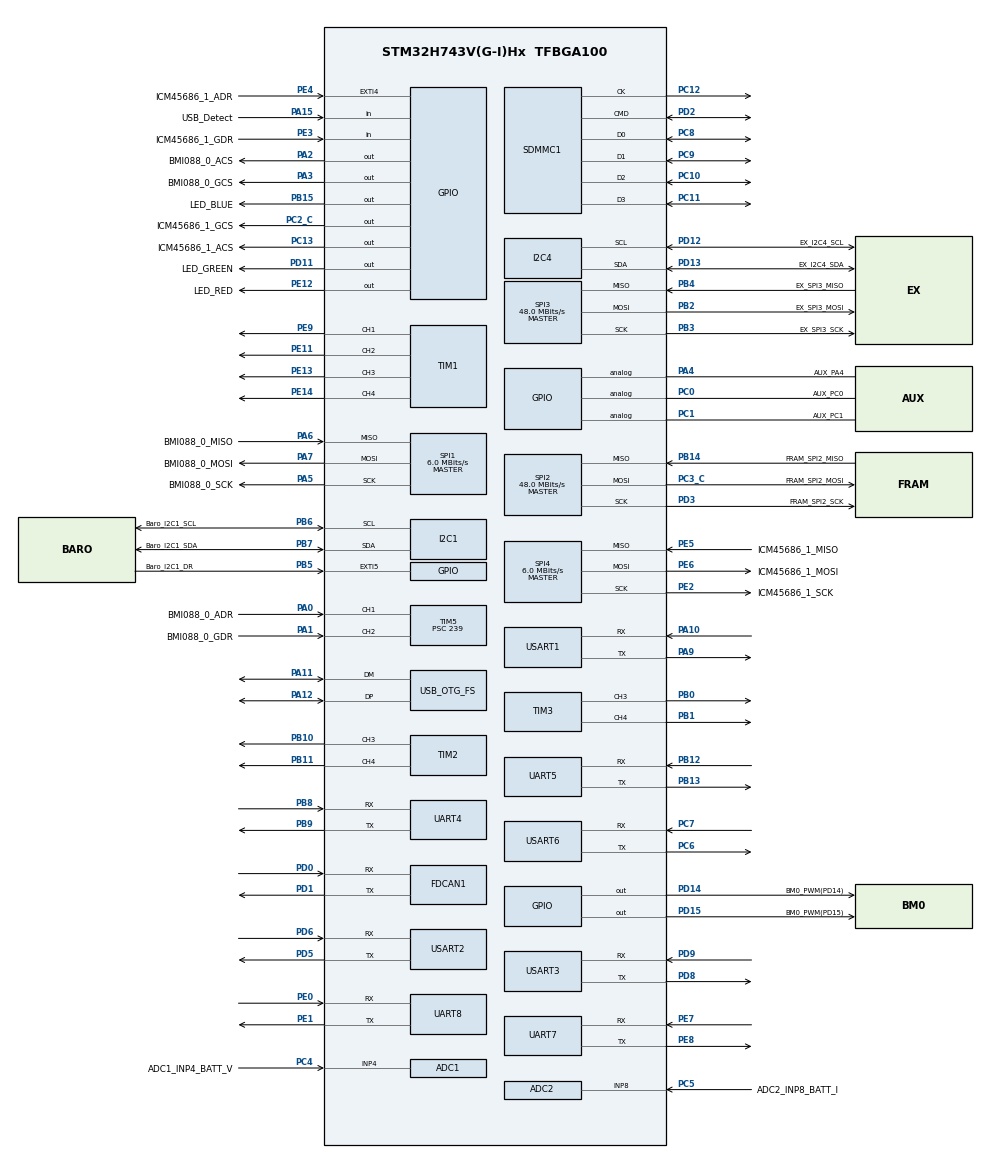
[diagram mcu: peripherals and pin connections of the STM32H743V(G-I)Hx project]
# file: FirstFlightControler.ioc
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ADC1.Channel-1\#ChannelRegularConversion=ADC_CHANNEL_4
ADC1.NbrOfConversionFlag=1
ADC1.OffsetNumber-1\#ChannelRegularConversion=ADC_OFFSET_NONE
ADC1.OffsetSignedSaturation-1\#ChannelRegularConversion=DISABLE
ADC1.Rank-1\#ChannelRegularConversion=1
ADC1.SamplingTime-1\#ChannelRegularConversion=ADC_SAMPLETIME_1CYCLE_5
ADC1.master=1
ADC2.Channel-0\#ChannelRegularConversion=ADC_CHANNEL_8
ADC2.ClockPrescaler=ADC_CLOCK_ASYNC_DIV1
ADC2.NbrOfConversionFlag=1
ADC2.OffsetNumber-0\#ChannelRegularConversion=ADC_OFFSET_NONE
ADC2.OffsetSignedSaturation-0\#ChannelRegularConversion=DISABLE
ADC2.Rank-0\#ChannelRegularConversion=1
ADC2.SamplingTime-0\#ChannelRegularConversion=ADC_SAMPLETIME_1CYCLE_5
CORTEX_M7.CPU_DCache=Disabled
CORTEX_M7.CPU_ICache=Enabled
CORTEX_M7.default_mode_Activation=1
Dma.Request0=USART1_RX
Dma.Request1=USART1_TX
Dma.Request10=SPI1_RX
Dma.Request11=SPI1_TX
Dma.Request12=SPI4_RX
Dma.Request13=SPI4_TX
Dma.Request2=USART2_RX
Dma.Request3=USART2_TX
Dma.Request4=USART3_RX
Dma.Request5=USART3_TX
Dma.Request6=UART5_RX
Dma.Request7=TIM1_UP
Dma.Request8=TIM2_UP
Dma.Request9=TIM3_UP
Dma.SPI1_RX.10.Direction=DMA_PERIPH_TO_MEMORY
Dma.SPI1_RX.10.EventEnable=DISABLE
Dma.SPI1_RX.10.FIFOMode=DMA_FIFOMODE_DISABLE
Dma.SPI1_RX.10.Instance=DMA1_Stream3
Dma.SPI1_RX.10.MemDataAlignment=DMA_MDATAALIGN_BYTE
Dma.SPI1_RX.10.MemInc=DMA_MINC_ENABLE
Dma.SPI1_RX.10.Mode=DMA_NORMAL
Dma.SPI1_RX.10.PeriphDataAlignment=DMA_PDATAALIGN_BYTE
Dma.SPI1_RX.10.PeriphInc=DMA_PINC_DISABLE
Dma.SPI1_RX.10.Polarity=HAL_DMAMUX_REQ_GEN_RISING
Dma.SPI1_RX.10.Priority=DMA_PRIORITY_VERY_HIGH
Dma.SPI1_RX.10.RequestNumber=1
Dma.SPI1_RX.10.SignalID=NONE
Dma.SPI1_RX.10.SyncEnable=DISABLE
Dma.SPI1_RX.10.SyncPolarity=HAL_DMAMUX_SYNC_NO_EVENT
Dma.SPI1_RX.10.SyncRequestNumber=1
Dma.SPI1_RX.10.SyncSignalID=NONE
Dma.SPI1_TX.11.Direction=DMA_MEMORY_TO_PERIPH
Dma.SPI1_TX.11.EventEnable=DISABLE
Dma.SPI1_TX.11.FIFOMode=DMA_FIFOMODE_DISABLE
Dma.SPI1_TX.11.Instance=DMA1_Stream4
Dma.SPI1_TX.11.MemDataAlignment=DMA_MDATAALIGN_BYTE
Dma.SPI1_TX.11.MemInc=DMA_MINC_ENABLE
Dma.SPI1_TX.11.Mode=DMA_NORMAL
Dma.SPI1_TX.11.PeriphDataAlignment=DMA_PDATAALIGN_BYTE
Dma.SPI1_TX.11.PeriphInc=DMA_PINC_DISABLE
Dma.SPI1_TX.11.Polarity=HAL_DMAMUX_REQ_GEN_RISING
Dma.SPI1_TX.11.Priority=DMA_PRIORITY_HIGH
Dma.SPI1_TX.11.RequestNumber=1
Dma.SPI1_TX.11.SignalID=NONE
Dma.SPI1_TX.11.SyncEnable=DISABLE
Dma.SPI1_TX.11.SyncPolarity=HAL_DMAMUX_SYNC_NO_EVENT
Dma.SPI1_TX.11.SyncRequestNumber=1
Dma.SPI1_TX.11.SyncSignalID=NONE
Dma.SPI4_RX.12.Direction=DMA_PERIPH_TO_MEMORY
Dma.SPI4_RX.12.EventEnable=DISABLE
Dma.SPI4_RX.12.FIFOMode=DMA_FIFOMODE_DISABLE
Dma.SPI4_RX.12.Instance=DMA1_Stream5
Dma.SPI4_RX.12.MemDataAlignment=DMA_MDATAALIGN_BYTE
Dma.SPI4_RX.12.MemInc=DMA_MINC_ENABLE
Dma.SPI4_RX.12.Mode=DMA_NORMAL
Dma.SPI4_RX.12.PeriphDataAlignment=DMA_PDATAALIGN_BYTE
Dma.SPI4_RX.12.PeriphInc=DMA_PINC_DISABLE
Dma.SPI4_RX.12.Polarity=HAL_DMAMUX_REQ_GEN_RISING
Dma.SPI4_RX.12.Priority=DMA_PRIORITY_VERY_HIGH
Dma.SPI4_RX.12.RequestNumber=1
Dma.SPI4_RX.12.SignalID=NONE
Dma.SPI4_RX.12.SyncEnable=DISABLE
Dma.SPI4_RX.12.SyncPolarity=HAL_DMAMUX_SYNC_NO_EVENT
Dma.SPI4_RX.12.SyncRequestNumber=1
Dma.SPI4_RX.12.SyncSignalID=NONE
Dma.SPI4_TX.13.Direction=DMA_MEMORY_TO_PERIPH
Dma.SPI4_TX.13.EventEnable=DISABLE
Dma.SPI4_TX.13.FIFOMode=DMA_FIFOMODE_DISABLE
Dma.SPI4_TX.13.Instance=DMA1_Stream6
Dma.SPI4_TX.13.MemDataAlignment=DMA_MDATAALIGN_BYTE
Dma.SPI4_TX.13.MemInc=DMA_MINC_ENABLE
Dma.SPI4_TX.13.Mode=DMA_NORMAL
Dma.SPI4_TX.13.PeriphDataAlignment=DMA_PDATAALIGN_BYTE
Dma.SPI4_TX.13.PeriphInc=DMA_PINC_DISABLE
Dma.SPI4_TX.13.Polarity=HAL_DMAMUX_REQ_GEN_RISING
Dma.SPI4_TX.13.Priority=DMA_PRIORITY_HIGH
Dma.SPI4_TX.13.RequestNumber=1
Dma.SPI4_TX.13.SignalID=NONE
Dma.SPI4_TX.13.SyncEnable=DISABLE
Dma.SPI4_TX.13.SyncPolarity=HAL_DMAMUX_SYNC_NO_EVENT
Dma.SPI4_TX.13.SyncRequestNumber=1
Dma.SPI4_TX.13.SyncSignalID=NONE
Dma.TIM1_UP.7.Direction=DMA_PERIPH_TO_MEMORY
Dma.TIM1_UP.7.EventEnable=DISABLE
Dma.TIM1_UP.7.FIFOMode=DMA_FIFOMODE_DISABLE
Dma.TIM1_UP.7.Instance=DMA1_Stream0
Dma.TIM1_UP.7.MemDataAlignment=DMA_MDATAALIGN_HALFWORD
Dma.TIM1_UP.7.MemInc=DMA_MINC_ENABLE
Dma.TIM1_UP.7.Mode=DMA_NORMAL
Dma.TIM1_UP.7.PeriphDataAlignment=DMA_PDATAALIGN_HALFWORD
Dma.TIM1_UP.7.PeriphInc=DMA_PINC_DISABLE
Dma.TIM1_UP.7.Polarity=HAL_DMAMUX_REQ_GEN_RISING
Dma.TIM1_UP.7.Priority=DMA_PRIORITY_LOW
Dma.TIM1_UP.7.RequestNumber=1
Dma.TIM1_UP.7.SignalID=NONE
Dma.TIM1_UP.7.SyncEnable=DISABLE
Dma.TIM1_UP.7.SyncPolarity=HAL_DMAMUX_SYNC_NO_EVENT
Dma.TIM1_UP.7.SyncRequestNumber=1
Dma.TIM1_UP.7.SyncSignalID=NONE
Dma.TIM2_UP.8.Direction=DMA_PERIPH_TO_MEMORY
Dma.TIM2_UP.8.EventEnable=DISABLE
Dma.TIM2_UP.8.FIFOMode=DMA_FIFOMODE_DISABLE
Dma.TIM2_UP.8.Instance=DMA1_Stream1
Dma.TIM2_UP.8.MemDataAlignment=DMA_MDATAALIGN_WORD
Dma.TIM2_UP.8.MemInc=DMA_MINC_ENABLE
Dma.TIM2_UP.8.Mode=DMA_NORMAL
Dma.TIM2_UP.8.PeriphDataAlignment=DMA_PDATAALIGN_WORD
Dma.TIM2_UP.8.PeriphInc=DMA_PINC_DISABLE
Dma.TIM2_UP.8.Polarity=HAL_DMAMUX_REQ_GEN_RISING
Dma.TIM2_UP.8.Priority=DMA_PRIORITY_LOW
Dma.TIM2_UP.8.RequestNumber=1
Dma.TIM2_UP.8.SignalID=NONE
Dma.TIM2_UP.8.SyncEnable=DISABLE
Dma.TIM2_UP.8.SyncPolarity=HAL_DMAMUX_SYNC_NO_EVENT
Dma.TIM2_UP.8.SyncRequestNumber=1
Dma.TIM2_UP.8.SyncSignalID=NONE
Dma.TIM3_UP.9.Direction=DMA_PERIPH_TO_MEMORY
Dma.TIM3_UP.9.EventEnable=DISABLE
Dma.TIM3_UP.9.FIFOMode=DMA_FIFOMODE_DISABLE
Dma.TIM3_UP.9.Instance=DMA1_Stream2
Dma.TIM3_UP.9.MemDataAlignment=DMA_MDATAALIGN_HALFWORD
Dma.TIM3_UP.9.MemInc=DMA_MINC_ENABLE
Dma.TIM3_UP.9.Mode=DMA_NORMAL
Dma.TIM3_UP.9.PeriphDataAlignment=DMA_PDATAALIGN_HALFWORD
Dma.TIM3_UP.9.PeriphInc=DMA_PINC_DISABLE
Dma.TIM3_UP.9.Polarity=HAL_DMAMUX_REQ_GEN_RISING
Dma.TIM3_UP.9.Priority=DMA_PRIORITY_LOW
Dma.TIM3_UP.9.RequestNumber=1
Dma.TIM3_UP.9.SignalID=NONE
Dma.TIM3_UP.9.SyncEnable=DISABLE
Dma.TIM3_UP.9.SyncPolarity=HAL_DMAMUX_SYNC_NO_EVENT
Dma.TIM3_UP.9.SyncRequestNumber=1
Dma.TIM3_UP.9.SyncSignalID=NONE
Dma.UART5_RX.6.Direction=DMA_PERIPH_TO_MEMORY
Dma.UART5_RX.6.EventEnable=DISABLE
Dma.UART5_RX.6.FIFOMode=DMA_FIFOMODE_DISABLE
Dma.UART5_RX.6.Instance=DMA2_Stream6
Dma.UART5_RX.6.MemDataAlignment=DMA_MDATAALIGN_BYTE
Dma.UART5_RX.6.MemInc=DMA_MINC_ENABLE
Dma.UART5_RX.6.Mode=DMA_NORMAL
Dma.UART5_RX.6.PeriphDataAlignment=DMA_PDATAALIGN_BYTE
Dma.UART5_RX.6.PeriphInc=DMA_PINC_DISABLE
Dma.UART5_RX.6.Polarity=HAL_DMAMUX_REQ_GEN_RISING
Dma.UART5_RX.6.Priority=DMA_PRIORITY_LOW
Dma.UART5_RX.6.RequestNumber=1
Dma.UART5_RX.6.SignalID=NONE
Dma.UART5_RX.6.SyncEnable=DISABLE
Dma.UART5_RX.6.SyncPolarity=HAL_DMAMUX_SYNC_NO_EVENT
Dma.UART5_RX.6.SyncRequestNumber=1
Dma.UART5_RX.6.SyncSignalID=NONE
Dma.USART1_RX.0.Direction=DMA_PERIPH_TO_MEMORY
Dma.USART1_RX.0.EventEnable=DISABLE
Dma.USART1_RX.0.FIFOMode=DMA_FIFOMODE_DISABLE
Dma.USART1_RX.0.Instance=DMA2_Stream0
Dma.USART1_RX.0.MemDataAlignment=DMA_MDATAALIGN_BYTE
Dma.USART1_RX.0.MemInc=DMA_MINC_ENABLE
Dma.USART1_RX.0.Mode=DMA_NORMAL
Dma.USART1_RX.0.PeriphDataAlignment=DMA_PDATAALIGN_BYTE
Dma.USART1_RX.0.PeriphInc=DMA_PINC_DISABLE
Dma.USART1_RX.0.Polarity=HAL_DMAMUX_REQ_GEN_RISING
Dma.USART1_RX.0.Priority=DMA_PRIORITY_LOW
Dma.USART1_RX.0.RequestNumber=1
Dma.USART1_RX.0.SignalID=NONE
Dma.USART1_RX.0.SyncEnable=DISABLE
Dma.USART1_RX.0.SyncPolarity=HAL_DMAMUX_SYNC_NO_EVENT
Dma.USART1_RX.0.SyncRequestNumber=1
Dma.USART1_RX.0.SyncSignalID=NONE
Dma.USART1_TX.1.Direction=DMA_MEMORY_TO_PERIPH
Dma.USART1_TX.1.EventEnable=DISABLE
Dma.USART1_TX.1.FIFOMode=DMA_FIFOMODE_DISABLE
Dma.USART1_TX.1.Instance=DMA2_Stream1
Dma.USART1_TX.1.MemDataAlignment=DMA_MDATAALIGN_BYTE
Dma.USART1_TX.1.MemInc=DMA_MINC_ENABLE
Dma.USART1_TX.1.Mode=DMA_NORMAL
Dma.USART1_TX.1.PeriphDataAlignment=DMA_PDATAALIGN_BYTE
Dma.USART1_TX.1.PeriphInc=DMA_PINC_DISABLE
Dma.USART1_TX.1.Polarity=HAL_DMAMUX_REQ_GEN_RISING
Dma.USART1_TX.1.Priority=DMA_PRIORITY_LOW
Dma.USART1_TX.1.RequestNumber=1
Dma.USART1_TX.1.SignalID=NONE
Dma.USART1_TX.1.SyncEnable=DISABLE
Dma.USART1_TX.1.SyncPolarity=HAL_DMAMUX_SYNC_NO_EVENT
Dma.USART1_TX.1.SyncRequestNumber=1
Dma.USART1_TX.1.SyncSignalID=NONE
Dma.USART2_RX.2.Direction=DMA_PERIPH_TO_MEMORY
Dma.USART2_RX.2.EventEnable=DISABLE
Dma.USART2_RX.2.FIFOMode=DMA_FIFOMODE_DISABLE
Dma.USART2_RX.2.Instance=DMA2_Stream2
Dma.USART2_RX.2.MemDataAlignment=DMA_MDATAALIGN_BYTE
Dma.USART2_RX.2.MemInc=DMA_MINC_ENABLE
Dma.USART2_RX.2.Mode=DMA_NORMAL
Dma.USART2_RX.2.PeriphDataAlignment=DMA_PDATAALIGN_BYTE
Dma.USART2_RX.2.PeriphInc=DMA_PINC_DISABLE
Dma.USART2_RX.2.Polarity=HAL_DMAMUX_REQ_GEN_RISING
Dma.USART2_RX.2.Priority=DMA_PRIORITY_LOW
Dma.USART2_RX.2.RequestNumber=1
Dma.USART2_RX.2.SignalID=NONE
Dma.USART2_RX.2.SyncEnable=DISABLE
Dma.USART2_RX.2.SyncPolarity=HAL_DMAMUX_SYNC_NO_EVENT
Dma.USART2_RX.2.SyncRequestNumber=1
Dma.USART2_RX.2.SyncSignalID=NONE
Dma.USART2_TX.3.Direction=DMA_MEMORY_TO_PERIPH
Dma.USART2_TX.3.EventEnable=DISABLE
Dma.USART2_TX.3.FIFOMode=DMA_FIFOMODE_DISABLE
Dma.USART2_TX.3.Instance=DMA2_Stream3
Dma.USART2_TX.3.MemDataAlignment=DMA_MDATAALIGN_BYTE
Dma.USART2_TX.3.MemInc=DMA_MINC_ENABLE
Dma.USART2_TX.3.Mode=DMA_NORMAL
Dma.USART2_TX.3.PeriphDataAlignment=DMA_PDATAALIGN_BYTE
Dma.USART2_TX.3.PeriphInc=DMA_PINC_DISABLE
Dma.USART2_TX.3.Polarity=HAL_DMAMUX_REQ_GEN_RISING
Dma.USART2_TX.3.Priority=DMA_PRIORITY_LOW
Dma.USART2_TX.3.RequestNumber=1
Dma.USART2_TX.3.SignalID=NONE
Dma.USART2_TX.3.SyncEnable=DISABLE
Dma.USART2_TX.3.SyncPolarity=HAL_DMAMUX_SYNC_NO_EVENT
Dma.USART2_TX.3.SyncRequestNumber=1
Dma.USART2_TX.3.SyncSignalID=NONE
Dma.USART3_RX.4.Direction=DMA_PERIPH_TO_MEMORY
Dma.USART3_RX.4.EventEnable=DISABLE
Dma.USART3_RX.4.FIFOMode=DMA_FIFOMODE_DISABLE
Dma.USART3_RX.4.Instance=DMA2_Stream4
Dma.USART3_RX.4.MemDataAlignment=DMA_MDATAALIGN_BYTE
Dma.USART3_RX.4.MemInc=DMA_MINC_ENABLE
Dma.USART3_RX.4.Mode=DMA_NORMAL
Dma.USART3_RX.4.PeriphDataAlignment=DMA_PDATAALIGN_BYTE
Dma.USART3_RX.4.PeriphInc=DMA_PINC_DISABLE
Dma.USART3_RX.4.Polarity=HAL_DMAMUX_REQ_GEN_RISING
Dma.USART3_RX.4.Priority=DMA_PRIORITY_LOW
Dma.USART3_RX.4.RequestNumber=1
Dma.USART3_RX.4.SignalID=NONE
Dma.USART3_RX.4.SyncEnable=DISABLE
Dma.USART3_RX.4.SyncPolarity=HAL_DMAMUX_SYNC_NO_EVENT
Dma.USART3_RX.4.SyncRequestNumber=1
Dma.USART3_RX.4.SyncSignalID=NONE
Dma.USART3_TX.5.Direction=DMA_MEMORY_TO_PERIPH
Dma.USART3_TX.5.EventEnable=DISABLE
Dma.USART3_TX.5.FIFOMode=DMA_FIFOMODE_DISABLE
Dma.USART3_TX.5.Instance=DMA2_Stream5
Dma.USART3_TX.5.MemDataAlignment=DMA_MDATAALIGN_BYTE
Dma.USART3_TX.5.MemInc=DMA_MINC_ENABLE
Dma.USART3_TX.5.Mode=DMA_NORMAL
Dma.USART3_TX.5.PeriphDataAlignment=DMA_PDATAALIGN_BYTE
Dma.USART3_TX.5.PeriphInc=DMA_PINC_DISABLE
Dma.USART3_TX.5.Polarity=HAL_DMAMUX_REQ_GEN_RISING
Dma.USART3_TX.5.Priority=DMA_PRIORITY_LOW
Dma.USART3_TX.5.RequestNumber=1
Dma.USART3_TX.5.SignalID=NONE
Dma.USART3_TX.5.SyncEnable=DISABLE
Dma.USART3_TX.5.SyncPolarity=HAL_DMAMUX_SYNC_NO_EVENT
Dma.USART3_TX.5.SyncRequestNumber=1
Dma.USART3_TX.5.SyncSignalID=NONE
FDCAN1.CalculateBaudRateNominal=333333
FDCAN1.CalculateTimeBitNominal=3000
FDCAN1.CalculateTimeQuantumNominal=1000.0
I2C1.Timing=0x10707DBC
I2C4.Timing=0x10707DBC
Mcu.Family=STM32H7
Mcu.Name=STM32H743V(G-I)Hx
Mcu.Package=TFBGA100
NVIC.DMA1_Stream0_IRQn=true\:0\:0\:false\:false\:true\:false\:true\:true
NVIC.DMA1_Stream1_IRQn=true\:0\:0\:false\:false\:true\:false\:true\:true
NVIC.DMA1_Stream2_IRQn=true\:0\:0\:false\:false\:true\:false\:true\:true
NVIC.DMA1_Stream3_IRQn=true\:3\:0\:false\:false\:true\:false\:true\:true
NVIC.DMA1_Stream4_IRQn=true\:4\:0\:false\:false\:true\:false\:true\:true
NVIC.DMA1_Stream5_IRQn=true\:3\:0\:false\:false\:true\:false\:true\:true
NVIC.DMA1_Stream6_IRQn=true\:4\:0\:false\:false\:true\:false\:true\:true
NVIC.DMA2_Stream0_IRQn=true\:0\:0\:false\:false\:true\:false\:true\:true
NVIC.DMA2_Stream1_IRQn=true\:0\:0\:false\:false\:true\:false\:true\:true
NVIC.DMA2_Stream2_IRQn=true\:0\:0\:false\:false\:true\:false\:true\:true
NVIC.DMA2_Stream3_IRQn=true\:0\:0\:false\:false\:true\:false\:true\:true
NVIC.DMA2_Stream4_IRQn=true\:0\:0\:false\:false\:true\:false\:true\:true
NVIC.DMA2_Stream5_IRQn=true\:0\:0\:false\:false\:true\:false\:true\:true
NVIC.DMA2_Stream6_IRQn=true\:0\:0\:false\:false\:true\:false\:true\:true
NVIC.EXTI4_IRQn=true\:2\:0\:true\:false\:true\:true\:true\:true
NVIC.OTG_FS_IRQn=true\:0\:0\:false\:false\:true\:false\:true\:true
NVIC.PriorityGroup=NVIC_PRIORITYGROUP_4
NVIC.SPI1_IRQn=true\:4\:0\:false\:false\:true\:false\:true\:true
NVIC.SPI4_IRQn=true\:4\:0\:false\:false\:true\:false\:true\:true
NVIC.TIM5_IRQn=true\:1\:0\:false\:false\:true\:true\:true\:true
PA0.GPIO_Label=BMI088_0_ADR
PA0.Signal=S_TIM5_CH1
PA1.GPIO_Label=BMI088_0_GDR
PA1.Signal=S_TIM5_CH2
PA10.Mode=Asynchronous
PA10.Signal=USART1_RX
PA11.Mode=Device_Only
PA11.Signal=USB_OTG_FS_DM
PA12.Mode=Device_Only
PA12.Signal=USB_OTG_FS_DP
PA13\ (JTMS/SWDIO).Mode=Serial_Wire
PA13\ (JTMS/SWDIO).Signal=DEBUG_JTMS-SWDIO
PA14\ (JTCK/SWCLK).Mode=Serial_Wire
PA14\ (JTCK/SWCLK).Signal=DEBUG_JTCK-SWCLK
PA15\ (JTDI).GPIO_Label=USB_Detect
PA15\ (JTDI).Signal=GPIO_Input
PA2.GPIO_Label=BMI088_0_ACS
PA2.PinState=GPIO_PIN_SET
PA2.Signal=GPIO_Output
PA3.GPIO_Label=BMI088_0_GCS
PA3.PinState=GPIO_PIN_SET
PA3.Signal=GPIO_Output
PA4.GPIO_Label=AUX_PA4
PA4.Signal=GPIO_Analog
PA5.GPIO_Label=BMI088_0_SCK
PA5.Mode=Full_Duplex_Master
PA5.Signal=SPI1_SCK
PA6.GPIO_Label=BMI088_0_MISO
PA6.Mode=Full_Duplex_Master
PA6.Signal=SPI1_MISO
PA7.GPIO_Label=BMI088_0_MOSI
PA7.Mode=Full_Duplex_Master
PA7.Signal=SPI1_MOSI
PA8.Signal=USART1_CK
PA9.Mode=Asynchronous
PA9.Signal=USART1_TX
PB0.Signal=S_TIM3_CH3
PB1.Signal=S_TIM3_CH4
PB10.Signal=S_TIM2_CH3
PB11.Signal=S_TIM2_CH4
PB12.Mode=Asynchronous
PB12.Signal=UART5_RX
PB13.Mode=Asynchronous
PB13.Signal=UART5_TX
PB14.GPIO_Label=FRAM_SPI2_MISO
PB14.Mode=Full_Duplex_Master
PB14.Signal=SPI2_MISO
PB15.GPIO_Label=LED_BLUE
PB15.Signal=GPIO_Output
PB2.GPIO_Label=EX_SPI3_MOSI
PB2.Mode=Full_Duplex_Master
PB2.Signal=SPI3_MOSI
PB3\ (JTDO/TRACESWO).GPIO_Label=EX_SPI3_SCK
PB3\ (JTDO/TRACESWO).Mode=Full_Duplex_Master
PB3\ (JTDO/TRACESWO).Signal=SPI3_SCK
PB4\ (NJTRST).GPIO_Label=EX_SPI3_MISO
PB4\ (NJTRST).Mode=Full_Duplex_Master
PB4\ (NJTRST).Signal=SPI3_MISO
PB5.GPIO_Label=Baro_I2C1_DR
PB5.Signal=GPXTI5
PB6.GPIO_Label=Baro_I2C1_SCL
PB6.Mode=I2C
PB6.Signal=I2C1_SCL
PB7.GPIO_Label=Baro_I2C1_SDA
PB7.Mode=I2C
PB7.Signal=I2C1_SDA
PB8.Mode=Asynchronous
PB8.Signal=UART4_RX
PB9.Mode=Asynchronous
PB9.Signal=UART4_TX
PC0.GPIO_Label=AUX_PC0
PC0.Signal=GPIO_Analog
PC1.GPIO_Label=AUX_PC1
PC1.Signal=GPIO_Analog
PC10.Mode=SD_4_bits_Wide_bus
PC10.Signal=SDMMC1_D2
PC11.Mode=SD_4_bits_Wide_bus
PC11.Signal=SDMMC1_D3
PC12.Mode=SD_4_bits_Wide_bus
PC12.Signal=SDMMC1_CK
PC13.GPIO_Label=ICM45686_1_ACS
PC13.PinState=GPIO_PIN_SET
PC13.Signal=GPIO_Output
PC14-OSC32_IN\ (OSC32_IN).Mode=LSE-External-Oscillator
PC14-OSC32_IN\ (OSC32_IN).Signal=RCC_OSC32_IN
PC15-OSC32_OUT\ (OSC32_OUT).Mode=LSE-External-Oscillator
PC15-OSC32_OUT\ (OSC32_OUT).Signal=RCC_OSC32_OUT
PC2_C.GPIO_Label=ICM45686_1_GCS
PC2_C.PinState=GPIO_PIN_SET
PC2_C.Signal=GPIO_Output
PC3_C.GPIO_Label=FRAM_SPI2_MOSI
PC3_C.Mode=Full_Duplex_Master
PC3_C.Signal=SPI2_MOSI
PC4.GPIO_Label=ADC1_INP4_BATT_V
PC4.Signal=ADCx_INP4
PC5.GPIO_Label=ADC2_INP8_BATT_I
PC5.Signal=SharedAnalog_PC5
PC6.Mode=Asynchronous
PC6.Signal=USART6_TX
PC7.Mode=Asynchronous
PC7.Signal=USART6_RX
PC8.Mode=SD_4_bits_Wide_bus
PC8.Signal=SDMMC1_D0
PC9.Mode=SD_4_bits_Wide_bus
PC9.Signal=SDMMC1_D1
PD0.Mode=FDCAN_Activate
PD0.Signal=FDCAN1_RX
PD1.Mode=FDCAN_Activate
PD1.Signal=FDCAN1_TX
PD10.Signal=USART3_CK
PD11.GPIO_Label=LED_GREEN
PD11.Signal=GPIO_Output
PD12.GPIO_Label=EX_I2C4_SCL
PD12.Mode=I2C
PD12.Signal=I2C4_SCL
PD13.GPIO_Label=EX_I2C4_SDA
PD13.Mode=I2C
PD13.Signal=I2C4_SDA
PD14.GPIO_Label=BM0_PWM(PD14)
PD14.Signal=GPIO_Output
PD15.GPIO_Label=BM0_PWM(PD15)
PD15.Signal=GPIO_Output
PD2.Mode=SD_4_bits_Wide_bus
PD2.Signal=SDMMC1_CMD
PD3.GPIO_Label=FRAM_SPI2_SCK
PD3.Mode=Full_Duplex_Master
PD3.Signal=SPI2_SCK
PD5.Mode=Asynchronous
PD5.Signal=USART2_TX
PD6.Mode=Asynchronous
PD6.Signal=USART2_RX
PD7.Signal=USART2_CK
PD8.Mode=Asynchronous
PD8.Signal=USART3_TX
PD9.Mode=Asynchronous
PD9.Signal=USART3_RX
PE0.Mode=Asynchronous
PE0.Signal=UART8_RX
PE1.Mode=Asynchronous
PE1.Signal=UART8_TX
PE11.Signal=S_TIM1_CH2
PE12.GPIO_Label=LED_RED
PE12.Signal=GPIO_Output
PE13.Signal=S_TIM1_CH3
PE14.Signal=S_TIM1_CH4
PE2.GPIO_Label=ICM45686_1_SCK
PE2.Mode=Full_Duplex_Master
PE2.Signal=SPI4_SCK
PE3.GPIO_Label=ICM45686_1_GDR
PE3.Signal=GPIO_Input
PE4.GPIO_Label=ICM45686_1_ADR
PE4.Signal=GPXTI4
PE5.GPIO_Label=ICM45686_1_MISO
PE5.Mode=Full_Duplex_Master
PE5.Signal=SPI4_MISO
PE6.GPIO_Label=ICM45686_1_MOSI
PE6.Mode=Full_Duplex_Master
PE6.Signal=SPI4_MOSI
PE7.Mode=Asynchronous
PE7.Signal=UART7_RX
PE8.Mode=Asynchronous
PE8.Signal=UART7_TX
PE9.Signal=S_TIM1_CH1
PH0-OSC_IN\ (PH0).Mode=HSE-External-Oscillator
PH0-OSC_IN\ (PH0).Signal=RCC_OSC_IN
PH1-OSC_OUT\ (PH1).Mode=HSE-External-Oscillator
PH1-OSC_OUT\ (PH1).Signal=RCC_OSC_OUT
ProjectManager.HeapSize=0x200
ProjectManager.StackSize=0x2000
ProjectManager.TargetToolchain=CMake
RCC.ADCFreq_Value=96000000
RCC.APB1Freq_Value=120000000
RCC.APB2Freq_Value=120000000
RCC.APB3Freq_Value=120000000
RCC.APB4Freq_Value=120000000
RCC.CortexFreq_Value=480000000
RCC.D1PPRE=RCC_APB3_DIV2
RCC.D2PPRE1=RCC_APB1_DIV2
RCC.D2PPRE2=RCC_APB2_DIV2
RCC.D3PPRE=RCC_APB4_DIV2
RCC.DIVM1=1
RCC.DIVM2=4
RCC.DIVM3=4
RCC.DIVN1=60
RCC.DIVN2=48
RCC.DIVN3=48
RCC.DIVQ1=4
RCC.DIVQ3=4
RCC.DIVR1=8
RCC.FDCANCLockSelection=RCC_FDCANCLKSOURCE_HSE
RCC.HCLKFreq_Value=240000000
RCC.HPRE=RCC_HCLK_DIV2
RCC.HSE_VALUE=16000000
RCC.I2C123CLockSelection=RCC_I2C123CLKSOURCE_HSI
RCC.I2C4CLockSelection=RCC_I2C4CLKSOURCE_HSI
RCC.PLL2FRACN=0
RCC.PLL2_VCI_Range-AdvancedSettings=RCC_PLL2VCIRANGE_0
RCC.PLL3FRACN=0
RCC.PLL3_VCI_Range-AdvancedSettings=RCC_PLL3VCIRANGE_0
RCC.PLLFRACN=0
RCC.SPI123CLockSelection=RCC_SPI123CLKSOURCE_PLL2
RCC.SYSCLKFreq_VALUE=480000000
RCC.SYSCLKSource=RCC_SYSCLKSOURCE_PLLCLK
RCC.Spi45ClockSelection=RCC_SPI45CLKSOURCE_PLL2
RCC.SupplySource=PWR_EXTERNAL_SOURCE_SUPPLY
RCC.USBCLockSelection=RCC_USBCLKSOURCE_PLL3
RCC.USBFreq_Value=48000000
SH.ADCx_INP4.0=ADC1_INP4,IN4-Single-Ended
SH.S_TIM1_CH1.0=TIM1_CH1,PWM Generation1 CH1
SH.S_TIM1_CH2.0=TIM1_CH2,PWM Generation2 CH2
SH.S_TIM1_CH3.0=TIM1_CH3,PWM Generation3 CH3
SH.S_TIM1_CH4.0=TIM1_CH4,PWM Generation4 CH4
SH.S_TIM2_CH3.0=TIM2_CH3,PWM Generation3 CH3
SH.S_TIM2_CH4.0=TIM2_CH4,PWM Generation4 CH4
SH.S_TIM3_CH3.0=TIM3_CH3,PWM Generation3 CH3
SH.S_TIM3_CH4.0=TIM3_CH4,PWM Generation4 CH4
SH.S_TIM5_CH1.0=TIM5_CH1,Input_Capture1_from_TI1
SH.S_TIM5_CH2.0=TIM5_CH2,Input_Capture2_from_TI2
SH.SharedAnalog_PC5.0=GPIO_Analog
SH.SharedAnalog_PC5.1=ADC1_INP8
SH.SharedAnalog_PC5.2=ADC2_INP8,IN8-Single-Ended
SPI1.BaudRatePrescaler=SPI_BAUDRATEPRESCALER_16
SPI1.CLKPhase=SPI_PHASE_2EDGE
SPI1.CLKPolarity=SPI_POLARITY_HIGH
SPI1.CalculateBaudRate=6.0 MBits/s
SPI1.DataSize=SPI_DATASIZE_8BIT
SPI1.Direction=SPI_DIRECTION_2LINES
SPI1.MasterKeepIOState=SPI_MASTER_KEEP_IO_STATE_ENABLE
SPI1.Mode=SPI_MODE_MASTER
SPI1.NSSPMode=SPI_NSS_PULSE_DISABLE
SPI1.VirtualType=VM_MASTER
SPI2.CalculateBaudRate=48.0 MBits/s
SPI2.Direction=SPI_DIRECTION_2LINES
SPI2.Mode=SPI_MODE_MASTER
SPI2.VirtualType=VM_MASTER
SPI3.CalculateBaudRate=48.0 MBits/s
SPI3.Direction=SPI_DIRECTION_2LINES
SPI3.Mode=SPI_MODE_MASTER
SPI3.VirtualType=VM_MASTER
SPI4.BaudRatePrescaler=SPI_BAUDRATEPRESCALER_16
SPI4.CLKPhase=SPI_PHASE_2EDGE
SPI4.CLKPolarity=SPI_POLARITY_HIGH
SPI4.CalculateBaudRate=6.0 MBits/s
SPI4.DataSize=SPI_DATASIZE_8BIT
SPI4.Direction=SPI_DIRECTION_2LINES
SPI4.MasterKeepIOState=SPI_MASTER_KEEP_IO_STATE_ENABLE
SPI4.Mode=SPI_MODE_MASTER
SPI4.NSSPMode=SPI_NSS_PULSE_DISABLE
SPI4.VirtualType=VM_MASTER
TIM1.Channel-PWM\ Generation1\ CH1=TIM_CHANNEL_1
TIM1.Channel-PWM\ Generation2\ CH2=TIM_CHANNEL_2
TIM1.Channel-PWM\ Generation3\ CH3=TIM_CHANNEL_3
TIM1.Channel-PWM\ Generation4\ CH4=TIM_CHANNEL_4
TIM2.Channel-PWM\ Generation3\ CH3=TIM_CHANNEL_3
TIM2.Channel-PWM\ Generation4\ CH4=TIM_CHANNEL_4
TIM3.Channel-PWM\ Generation3\ CH3=TIM_CHANNEL_3
TIM3.Channel-PWM\ Generation4\ CH4=TIM_CHANNEL_4
TIM5.Channel-Input_Capture1_from_TI1=TIM_CHANNEL_1
TIM5.Channel-Input_Capture2_from_TI2=TIM_CHANNEL_2
TIM5.Channel-Output\ Compare3\ No\ Output=TIM_CHANNEL_3
TIM5.Period=0xFFFFFFFF
TIM5.Prescaler=239
USART1.VirtualMode-Asynchronous=VM_ASYNC
USART2.VirtualMode-Asynchronous=VM_ASYNC
USART3.VirtualMode-Asynchronous=VM_ASYNC
USART6.VirtualMode=VM_ASYNC
USB_DEVICE.CLASS_NAME_FS=CDC
USB_DEVICE.VirtualMode-CDC_FS=Cdc
USB_DEVICE.VirtualModeFS=Cdc_FS
USB_OTG_FS.VirtualMode=Device_Only
VP_MEMORYMAP_VS_MEMORYMAP.Mode=CurAppReg
VP_TIM5_VS_ClockSourceINT.Mode=Internal
VP_TIM5_VS_no_output3.Mode=Output Compare3 No Output
VP_USB_DEVICE_VS_USB_DEVICE_CDC_FS.Mode=CDC_FS
board=custom

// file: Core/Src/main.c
/* USER CODE BEGIN Header */
/**
  ******************************************************************************
  * @file           : main.c
  * @brief          : Main program body
  ******************************************************************************
  * @attention
  *
  * Copyright (c) 2026 STMicroelectronics.
  * All rights reserved.
  *
  * This software is licensed under terms that can be found in the LICENSE file
  * in the root directory of this software component.
  * If no LICENSE file comes with this software, it is provided AS-IS.
  *
  ******************************************************************************
  */
/* USER CODE END Header */
#include "main.h"
#include "adc.h"
#include "dma.h"
#include "fdcan.h"
#include "i2c.h"
#include "sdmmc.h"
#include "spi.h"
#include "tim.h"
#include "usart.h"
#include "usb_device.h"
#include "gpio.h"

/* USER CODE BEGIN Includes */
#include "app.h"
/* USER CODE END Includes */

/* USER CODE BEGIN PD */
/* HAL_SD_Init fails when no card is inserted. Storage will initialize it on demand. */
#define MX_SDMMC1_SD_Init() ((void)0)
/* USER CODE END PD */

void SystemClock_Config(void);
void PeriphCommonClock_Config(void);
static void MPU_Config(void);

int main(void)
{

  /* MPU Configuration--------------------------------------------------------*/
  MPU_Config();

  /* Enable the CPU Cache */

  /* Enable I-Cache---------------------------------------------------------*/
  SCB_EnableICache();

  /* MCU Configuration--------------------------------------------------------*/

  /* Reset of all peripherals, Initializes the Flash interface and the Systick. */
  HAL_Init();

  /* USER CODE BEGIN Init */

  /* I-cache is generated from the IOC; D-cache stays off for DMA coherency. */

  /* Drive both IMU heater enables low before clock configuration can enter
     Error_Handler. MX_GPIO_Init repeats this fail-off configuration later. */
  __HAL_RCC_GPIOD_CLK_ENABLE();
  HAL_GPIO_WritePin(GPIOD, BM0_PWM_Pin|BM0_PWMD14_Pin, GPIO_PIN_RESET);
  GPIO_InitTypeDef heater_off = {0};
  heater_off.Pin = BM0_PWM_Pin|BM0_PWMD14_Pin;
  heater_off.Mode = GPIO_MODE_OUTPUT_PP;
  heater_off.Pull = GPIO_NOPULL;
  heater_off.Speed = GPIO_SPEED_FREQ_LOW;
  HAL_GPIO_Init(GPIOD, &heater_off);

  /* USER CODE END Init */

  /* Configure the system clock */
  SystemClock_Config();

  /* Configure the peripherals common clocks */
  PeriphCommonClock_Config();

  /* Initialize all configured peripherals */
  MX_GPIO_Init();
  MX_DMA_Init();
  MX_ADC1_Init();
  MX_ADC2_Init();
  MX_FDCAN1_Init();
  MX_I2C1_Init();
  MX_I2C4_Init();
  MX_SDMMC1_SD_Init();
  MX_SPI1_Init();
  MX_SPI2_Init();
  MX_SPI3_Init();
  MX_SPI4_Init();
  MX_TIM1_Init();
  MX_TIM2_Init();
  MX_TIM3_Init();
  MX_UART4_Init();
  MX_UART5_Init();
  MX_UART7_Init();
  MX_UART8_Init();
  MX_USART1_UART_Init();
  MX_USART2_UART_Init();
  MX_USART3_UART_Init();
  MX_USART6_UART_Init();
  MX_USB_DEVICE_Init();
  MX_TIM5_Init();
  /* USER CODE BEGIN 2 */
  app_init();
  /* USER CODE END 2 */

  /* Infinite loop */
  while (1)
  {

    /* USER CODE BEGIN 3 */
    app_process();
  }
  /* USER CODE END 3 */
}

void SystemClock_Config(void)
{
  RCC_OscInitTypeDef RCC_OscInitStruct = {0};
  RCC_ClkInitTypeDef RCC_ClkInitStruct = {0};

  /** Supply configuration update enable
  */
  HAL_PWREx_ConfigSupply(PWR_EXTERNAL_SOURCE_SUPPLY);

  /** Configure the main internal regulator output voltage
  */
  __HAL_PWR_VOLTAGESCALING_CONFIG(PWR_REGULATOR_VOLTAGE_SCALE0);

  while(!__HAL_PWR_GET_FLAG(PWR_FLAG_VOSRDY)) {}

  /** Initializes the RCC Oscillators according to the specified parameters
  * in the RCC_OscInitTypeDef structure.
  */
  RCC_OscInitStruct.OscillatorType = RCC_OSCILLATORTYPE_HSI|RCC_OSCILLATORTYPE_HSE;
  RCC_OscInitStruct.HSEState = RCC_HSE_ON;
  RCC_OscInitStruct.HSIState = RCC_HSI_DIV1;
  RCC_OscInitStruct.HSICalibrationValue = RCC_HSICALIBRATION_DEFAULT;
  RCC_OscInitStruct.PLL.PLLState = RCC_PLL_ON;
  RCC_OscInitStruct.PLL.PLLSource = RCC_PLLSOURCE_HSE;
  RCC_OscInitStruct.PLL.PLLM = 1;
  RCC_OscInitStruct.PLL.PLLN = 60;
  RCC_OscInitStruct.PLL.PLLP = 2;
  RCC_OscInitStruct.PLL.PLLQ = 4;
  RCC_OscInitStruct.PLL.PLLR = 8;
  RCC_OscInitStruct.PLL.PLLRGE = RCC_PLL1VCIRANGE_3;
  RCC_OscInitStruct.PLL.PLLVCOSEL = RCC_PLL1VCOWIDE;
  RCC_OscInitStruct.PLL.PLLFRACN = 0;
  if (HAL_RCC_OscConfig(&RCC_OscInitStruct) != HAL_OK)
  {
    Error_Handler();
  }

  /** Initializes the CPU, AHB and APB buses clocks
  */
  RCC_ClkInitStruct.ClockType = RCC_CLOCKTYPE_HCLK|RCC_CLOCKTYPE_SYSCLK
                              |RCC_CLOCKTYPE_PCLK1|RCC_CLOCKTYPE_PCLK2
                              |RCC_CLOCKTYPE_D3PCLK1|RCC_CLOCKTYPE_D1PCLK1;
  RCC_ClkInitStruct.SYSCLKSource = RCC_SYSCLKSOURCE_PLLCLK;
  RCC_ClkInitStruct.SYSCLKDivider = RCC_SYSCLK_DIV1;
  RCC_ClkInitStruct.AHBCLKDivider = RCC_HCLK_DIV2;
  RCC_ClkInitStruct.APB3CLKDivider = RCC_APB3_DIV2;
  RCC_ClkInitStruct.APB1CLKDivider = RCC_APB1_DIV2;
  RCC_ClkInitStruct.APB2CLKDivider = RCC_APB2_DIV2;
  RCC_ClkInitStruct.APB4CLKDivider = RCC_APB4_DIV2;

  if (HAL_RCC_ClockConfig(&RCC_ClkInitStruct, FLASH_LATENCY_4) != HAL_OK)
  {
    Error_Handler();
  }
}

void PeriphCommonClock_Config(void)
{
  RCC_PeriphCLKInitTypeDef PeriphClkInitStruct = {0};

  /** Initializes the peripherals clock
  */
  PeriphClkInitStruct.PeriphClockSelection = RCC_PERIPHCLK_ADC|RCC_PERIPHCLK_SPI3
                              |RCC_PERIPHCLK_SPI2|RCC_PERIPHCLK_SPI1
                              |RCC_PERIPHCLK_SPI4;
  PeriphClkInitStruct.PLL2.PLL2M = 4;
  PeriphClkInitStruct.PLL2.PLL2N = 48;
  PeriphClkInitStruct.PLL2.PLL2P = 2;
  PeriphClkInitStruct.PLL2.PLL2Q = 2;
  PeriphClkInitStruct.PLL2.PLL2R = 2;
  PeriphClkInitStruct.PLL2.PLL2RGE = RCC_PLL2VCIRANGE_2;
  PeriphClkInitStruct.PLL2.PLL2VCOSEL = RCC_PLL2VCOWIDE;
  PeriphClkInitStruct.PLL2.PLL2FRACN = 0;
  PeriphClkInitStruct.Spi123ClockSelection = RCC_SPI123CLKSOURCE_PLL2;
  PeriphClkInitStruct.Spi45ClockSelection = RCC_SPI45CLKSOURCE_PLL2;
  PeriphClkInitStruct.AdcClockSelection = RCC_ADCCLKSOURCE_PLL2;
  if (HAL_RCCEx_PeriphCLKConfig(&PeriphClkInitStruct) != HAL_OK)
  {
    Error_Handler();
  }
}

 /* MPU Configuration */

void MPU_Config(void)
{
  MPU_Region_InitTypeDef MPU_InitStruct = {0};

  /* Disables the MPU */
  HAL_MPU_Disable();

  /** Initializes and configures the Region and the memory to be protected
  */
  MPU_InitStruct.Enable = MPU_REGION_ENABLE;
  MPU_InitStruct.Number = MPU_REGION_NUMBER0;
  MPU_InitStruct.BaseAddress = 0x0;
  MPU_InitStruct.Size = MPU_REGION_SIZE_4GB;
  MPU_InitStruct.SubRegionDisable = 0x87;
  MPU_InitStruct.TypeExtField = MPU_TEX_LEVEL0;
  MPU_InitStruct.AccessPermission = MPU_REGION_NO_ACCESS;
  MPU_InitStruct.DisableExec = MPU_INSTRUCTION_ACCESS_DISABLE;
  MPU_InitStruct.IsShareable = MPU_ACCESS_SHAREABLE;
  MPU_InitStruct.IsCacheable = MPU_ACCESS_NOT_CACHEABLE;
  MPU_InitStruct.IsBufferable = MPU_ACCESS_NOT_BUFFERABLE;

  HAL_MPU_ConfigRegion(&MPU_InitStruct);
  /* Enables the MPU */
  HAL_MPU_Enable(MPU_PRIVILEGED_DEFAULT);

}

void Error_Handler(void)
{
  __disable_irq();
  while (1)
  {
  }
}
